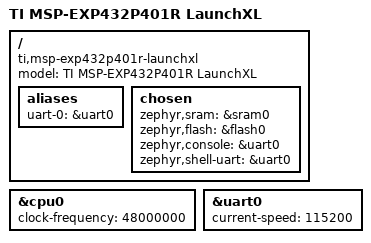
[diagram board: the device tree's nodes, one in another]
/* SPDX-License-Identifier: Apache-2.0 */

/dts-v1/;

#include <ti/msp432p401r.dtsi>

/ {
	model = "TI MSP-EXP432P401R LaunchXL";
	compatible = "ti,msp-exp432p401r-launchxl","ti,msp432p401r",
						"ti,msp432p4xx";

	aliases {
		uart-0 = &uart0;
	};

	chosen {
		zephyr,sram = &sram0;
		zephyr,flash = &flash0;
		zephyr,console = &uart0;
		zephyr,shell-uart = &uart0;
	};
};

&cpu0 {
	clock-frequency = <48000000>;
};

&uart0 {
	status = "okay";
	current-speed = <115200>;
};

